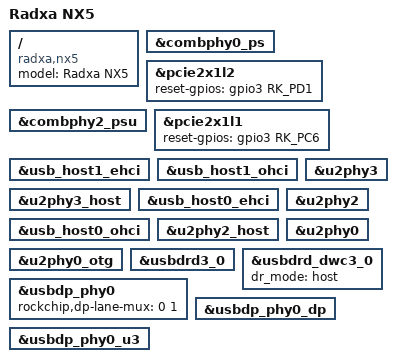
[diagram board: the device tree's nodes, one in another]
// SPDX-License-Identifier: (GPL-2.0+ OR MIT)
/*
 * Copyright (c) 2022 Rockchip Electronics Co., Ltd.
 * Copyright (c) 2022 Radxa Limited
 *
 */

/dts-v1/;

#include "rk3588s-radxa-nx5-module.dtsi"

/ {
	model = "Radxa NX5";
	compatible = "radxa,nx5", "rockchip,rk3588";
};

&combphy0_ps {
	status = "okay";
};

&pcie2x1l2 {
	reset-gpios = <&gpio3 RK_PD1 GPIO_ACTIVE_HIGH>;
	status = "okay";
};

&combphy2_psu {
	status = "okay";
};

&pcie2x1l1 {
	reset-gpios = <&gpio3 RK_PC6 GPIO_ACTIVE_HIGH>;
	status = "okay";
};

&usb_host1_ehci {
	status = "okay";
};

&usb_host1_ohci {
	status = "okay";
};

&u2phy3 {
	status = "okay";
};

&u2phy3_host {
	status = "okay";
};

&usb_host0_ehci {
	status = "okay";
};

&usb_host0_ohci {
	status = "okay";
};

&u2phy2 {
	status = "okay";
};

&u2phy2_host {
	status = "okay";
};

&u2phy0 {
	status = "okay";
};

&u2phy0_otg {
	status = "okay";
};

&usbdrd3_0 {
	status = "okay";
};

&usbdrd_dwc3_0 {
	status = "okay";
	dr_mode = "host";
};

&usbdp_phy0 {
	status = "okay";
	rockchip,dp-lane-mux = < 0 1 >;
};

&usbdp_phy0_dp {
	status = "okay";
};

&usbdp_phy0_u3 {
	status = "okay";
};
